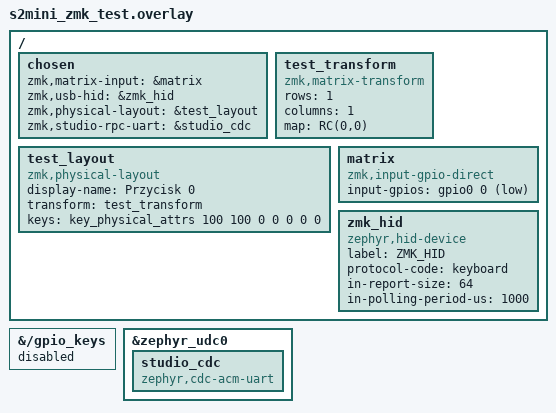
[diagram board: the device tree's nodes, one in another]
#include <dt-bindings/zmk/matrix_transform.h>
#include <physical_layouts.dtsi>

/*
 * Test ZMK na S2 mini: jeden klawisz = przycisk "0" (GPIO0).
 * Wymaga też shielda s2mini_usb (węzeł USB OTG).
 * SPDX-License-Identifier: MIT
 */

/ {
    chosen {
        zmk,matrix-input = &matrix;
        zmk,usb-hid = &zmk_hid;
        zmk,physical-layout = &test_layout;
        zmk,studio-rpc-uart = &studio_cdc;
    };

    test_transform: test_transform {
        compatible = "zmk,matrix-transform";
        rows = <1>;
        columns = <1>;
        map = <RC(0,0)>;
    };

    test_layout: test_layout {
        compatible = "zmk,physical-layout";
        display-name = "Przycisk 0";
        transform = <&test_transform>;
        keys = <&key_physical_attrs 100 100 0 0 0 0 0>;
    };

    matrix: matrix {
        compatible = "zmk,input-gpio-direct";
        input-gpios = <&gpio0 0 (GPIO_ACTIVE_LOW | GPIO_PULL_UP)>;
    };

    zmk_hid: zmk_hid {
        compatible = "zephyr,hid-device";
        label = "ZMK_HID";
        protocol-code = "keyboard";
        in-report-size = <64>;
        in-polling-period-us = <1000>;
    };
};

/* Przycisk "0" obsługuje teraz ZMK, nie sterownik gpio-keys z płytki */
&{/gpio_keys} {
    status = "disabled";
};

/* Port szeregowy USB (CDC ACM) dla ZMK Studio */
&zephyr_udc0 {
    studio_cdc: studio_cdc {
        compatible = "zephyr,cdc-acm-uart";
    };
};
